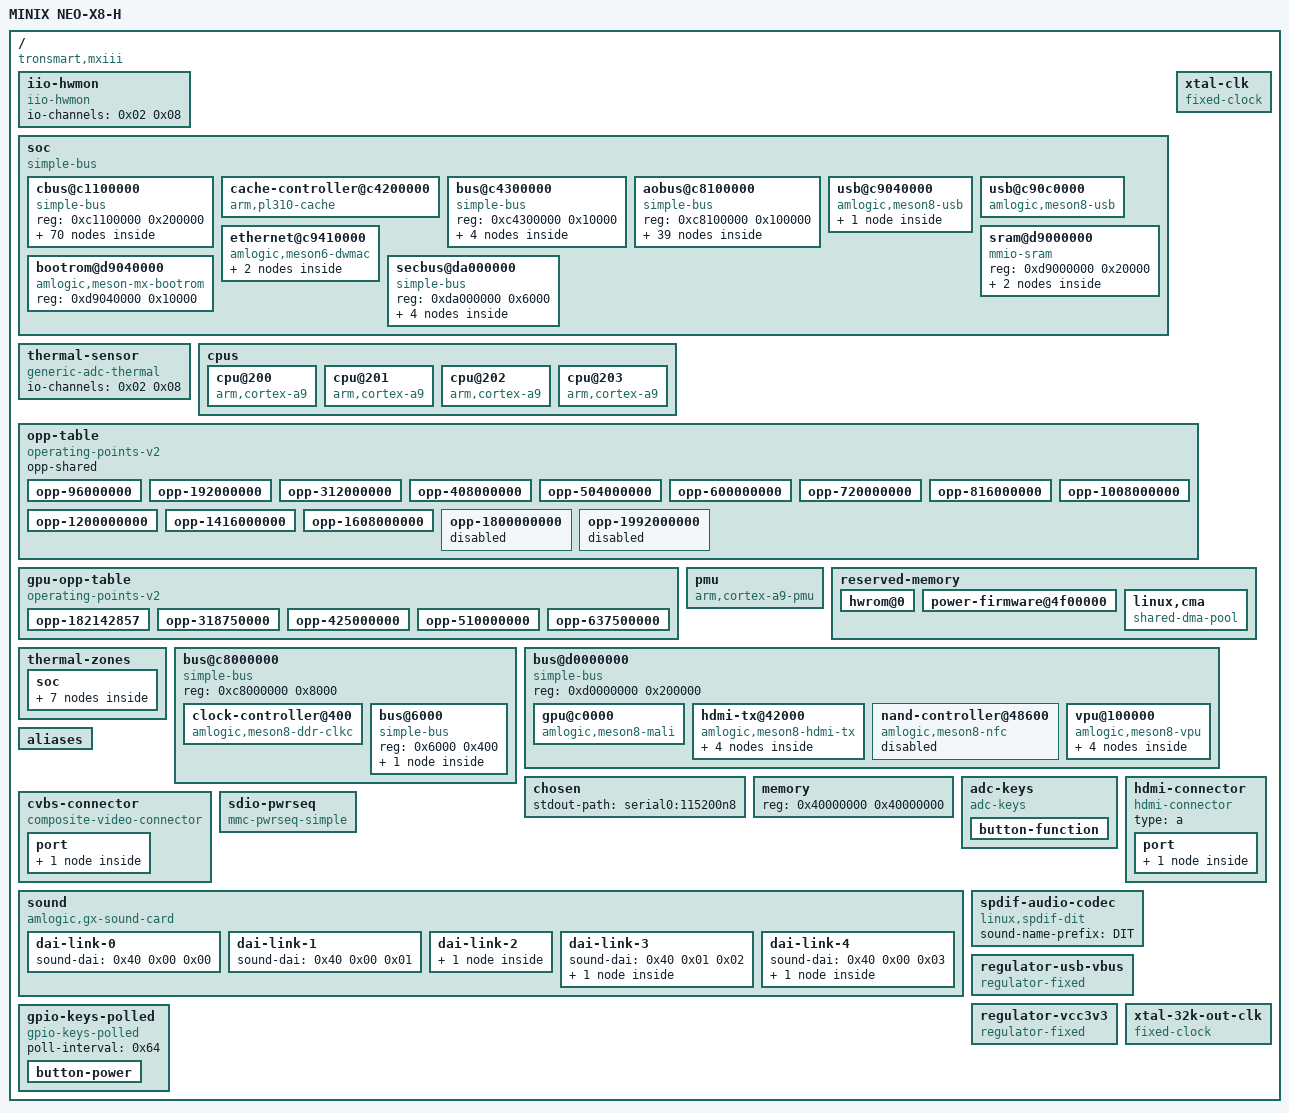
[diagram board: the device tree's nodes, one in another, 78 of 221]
/dts-v1/;

/ {
	#address-cells = <0x01>;
	#size-cells = <0x01>;
	interrupt-parent = <0x01>;
	model = "MINIX NEO-X8-H";
	compatible = "tronsmart,mxiii", "amlogic,meson8m2";

	iio-hwmon {
		compatible = "iio-hwmon";
		io-channels = <0x02 0x08>;
	};

	soc {
		compatible = "simple-bus";
		#address-cells = <0x01>;
		#size-cells = <0x01>;
		ranges;

		cbus@c1100000 {
			compatible = "simple-bus";
			reg = <0xc1100000 0x200000>;
			#address-cells = <0x01>;
			#size-cells = <0x01>;
			ranges = <0x00 0xc1100000 0x200000>;

			system-controller@4000 {
				compatible = "amlogic,meson-hhi-sysctrl", "simple-mfd", "syscon";
				reg = <0x4000 0x400>;
				#address-cells = <0x01>;
				#size-cells = <0x01>;
				ranges = <0x00 0x4000 0x400>;
				phandle = <0x0e>;

				video-dac@2f4 {
					compatible = "amlogic,meson8-cvbs-dac", "amlogic,meson-cvbs-dac";
					reg = <0x2f4 0x08>;
					#phy-cells = <0x00>;
					status = "okay";
					clocks = <0x03 0xab>;
					nvmem-cells = <0x04>;
					nvmem-cell-names = "cvbs_trimming";
					phandle = <0x38>;
				};

				clock-controller@0 {
					compatible = "amlogic,meson8-clkc";
					reg = <0x00 0x39c>;
					clocks = <0x05 0x06 0x01>;
					clock-names = "xtal", "ddr_pll";
					#clock-cells = <0x01>;
					#reset-cells = <0x01>;
					phandle = <0x03>;
				};

				power-controller@100 {
					compatible = "amlogic,meson8-pwrc";
					reg = <0x100 0x10>;
					#power-domain-cells = <0x01>;
					amlogic,ao-sysctrl = <0x07>;
					clocks = <0x03 0xbe>;
					clock-names = "vpu";
					assigned-clocks = <0x03 0xbe>;
					assigned-clock-rates = <0x15b68f12>;
					phandle = <0x21>;
				};

				hdmi-phy@3a0 {
					compatible = "amlogic,meson8-hdmi-tx-phy";
					clocks = <0x03 0x84>;
					reg = <0x3a0 0x0c>;
					#phy-cells = <0x00>;
					phandle = <0x32>;
				};
			};

			audio-controller@5400 {
				compatible = "amlogic,aiu-meson8", "amlogic,aiu";
				#sound-dai-cells = <0x02>;
				sound-name-prefix = "AIU";
				reg = <0x5400 0x2ac>;
				interrupts = <0x00 0x30 0x01 0x00 0x32 0x01>;
				interrupt-names = "i2s", "spdif";
				status = "okay";
				clocks = <0x03 0x26 0x03 0x28 0x03 0x50 0x03 0xd1 0x03 0x2c 0x03 0x27 0x03 0x51 0x03 0xd4 0x03 0xd5>;
				clock-names = "pclk", "i2s_pclk", "i2s_aoclk", "i2s_mclk", "i2s_mixer", "spdif_pclk", "spdif_aoclk", "spdif_mclk", "spdif_mclk_sel";
				resets = <0x08 0x06>;
				pinctrl-0 = <0x09 0x0a 0x0b 0x0c 0x0d>;
				pinctrl-names = "default";
				phandle = <0x40>;
			};

			assist@7c00 {
				compatible = "amlogic,meson-mx-assist", "syscon";
				reg = <0x7c00 0x200>;
			};

			rng@8100 {
				compatible = "amlogic,meson8-rng", "amlogic,meson-rng";
				reg = <0x8100 0x08>;
				clocks = <0x03 0x19>;
				clock-names = "core";
			};

			serial@84c0 {
				compatible = "amlogic,meson8-uart";
				reg = <0x84c0 0x18>;
				interrupts = <0x00 0x1a 0x01>;
				fifo-size = <0x80>;
				status = "disabled";
				clocks = <0x05 0x03 0x1a 0x03 0x0a>;
				clock-names = "xtal", "pclk", "baud";
			};

			serial@84dc {
				compatible = "amlogic,meson8-uart";
				reg = <0x84dc 0x18>;
				interrupts = <0x00 0x4b 0x01>;
				status = "disabled";
				clocks = <0x05 0x03 0x30 0x03 0x0a>;
				clock-names = "xtal", "pclk", "baud";
			};

			i2c@8500 {
				compatible = "amlogic,meson6-i2c";
				reg = <0x8500 0x20>;
				interrupts = <0x00 0x15 0x01>;
				#address-cells = <0x01>;
				#size-cells = <0x00>;
				status = "disabled";
				clocks = <0x03 0x0a>;
			};

			pwm@8550 {
				compatible = "amlogic,meson8-pwm", "amlogic,meson8b-pwm";
				reg = <0x8550 0x10>;
				#pwm-cells = <0x03>;
				status = "disabled";
			};

			pwm@8650 {
				compatible = "amlogic,meson8-pwm", "amlogic,meson8b-pwm";
				reg = <0x8650 0x10>;
				#pwm-cells = <0x03>;
				status = "disabled";
			};

			adc@8680 {
				compatible = "amlogic,meson8-saradc", "amlogic,meson-saradc";
				reg = <0x8680 0x34>;
				#io-channel-cells = <0x01>;
				interrupts = <0x00 0x49 0x01>;
				status = "okay";
				clocks = <0x05 0x03 0x17>;
				clock-names = "clkin", "core";
				amlogic,hhi-sysctrl = <0x0e>;
				nvmem-cells = <0x0f>;
				nvmem-cell-names = "temperature_calib";
				vref-supply = <0x10>;
				phandle = <0x02>;
			};

			serial@8700 {
				compatible = "amlogic,meson8-uart";
				reg = <0x8700 0x18>;
				interrupts = <0x00 0x5d 0x01>;
				status = "disabled";
				clocks = <0x05 0x03 0x44 0x03 0x0a>;
				clock-names = "xtal", "pclk", "baud";
			};

			i2c@87c0 {
				compatible = "amlogic,meson6-i2c";
				reg = <0x87c0 0x20>;
				interrupts = <0x00 0x80 0x01>;
				#address-cells = <0x01>;
				#size-cells = <0x00>;
				status = "disabled";
				clocks = <0x03 0x0a>;
			};

			phy@8800 {
				compatible = "amlogic,meson8-usb2-phy", "amlogic,meson-mx-usb2-phy";
				#phy-cells = <0x00>;
				reg = <0x8800 0x20>;
				gpio-controller;
				#gpio-cells = <0x02>;
				status = "okay";
				clocks = <0x03 0x37 0x03 0x32>;
				clock-names = "usb_general", "usb";
				resets = <0x08 0x22>;
				phandle = <0x1e>;
			};

			phy@8820 {
				compatible = "amlogic,meson8-usb2-phy", "amlogic,meson-mx-usb2-phy";
				#phy-cells = <0x00>;
				reg = <0x8820 0x20>;
				status = "okay";
				clocks = <0x03 0x37 0x03 0x33>;
				clock-names = "usb_general", "usb";
				resets = <0x08 0x22>;
				phandle = <0x20>;
			};

			mmc@8c20 {
				compatible = "amlogic,meson8-sdio", "amlogic,meson-mx-sdio";
				reg = <0x8c20 0x20>;
				interrupts = <0x00 0x1c 0x01>;
				#address-cells = <0x01>;
				#size-cells = <0x00>;
				status = "okay";
				clocks = <0x03 0x1e 0x03 0x0a>;
				clock-names = "core", "clkin";
				pinctrl-0 = <0x11>;
				pinctrl-names = "default";

				slot@0 {
					compatible = "mmc-slot";
					reg = <0x01>;
					bus-width = <0x04>;
					max-frequency = <0x2faf080>;
					no-mmc;
					no-sdio;
					cap-sd-highspeed;
					disable-wp;
					cd-gpios = <0x12 0x64 0x01>;
					vmmc-supply = <0x13>;
				};
			};

			spi@8c80 {
				compatible = "amlogic,meson6-spifc";
				reg = <0x8c80 0x80>;
				#address-cells = <0x01>;
				#size-cells = <0x00>;
				status = "disabled";
				clocks = <0x03 0x0a>;
			};

			/* SDHC: AP6330 (BCM4330) WiFi on the port-A / GPIOX pads */
			mmc@8e00 {
				compatible = "amlogic,meson8-sdhc", "amlogic,meson-mx-sdhc";
				reg = <0x8e00 0x42>;
				interrupts = <0x00 0x4e 0x01>;
				status = "okay";
				clocks = <0x05 0x03 0x07 0x03 0x06 0x03 0x08 0x03 0x1b>;
				clock-names = "clkin0", "clkin1", "clkin2", "clkin3", "pclk";
				pinctrl-0 = <0x51>;
				pinctrl-names = "default";
				#address-cells = <0x01>;
				#size-cells = <0x00>;
				bus-width = <0x04>;
				max-frequency = <0x17d7840>;
				disable-wp;
				non-removable;
				no-mmc;
				no-sd;
				cap-sd-highspeed;
				keep-power-in-suspend;
				mmc-pwrseq = <0x15>;
				vmmc-supply = <0x13>;
				vqmmc-supply = <0x13>;

				wifi@1 {
					compatible = "brcm,bcm4329-fmac";
					reg = <0x01>;
					/*
					 * Out-of-band host-wake on GPIOX_21 (from Android wifi/interrupt_pin),
					 * active-high level. REQUIRES the irq-meson-gpio IRQCHIP_SKIP_SET_WAKE
					 * kernel patch; without it brcmfmac enable_irq_wake() aborts with -6.
					 * interrupt-parent 0x24 = interrupt-controller@9880 (meson8-gpio-intc).
					 */
					interrupt-parent = <0x24>;
					interrupts = <0x15 0x04>;
					interrupt-names = "host-wake";
				};
			};

			interrupt-controller@9880 {
				compatible = "amlogic,meson8-gpio-intc", "amlogic,meson-gpio-intc";
				reg = <0x9880 0x10>;
				interrupt-controller;
				#interrupt-cells = <0x02>;
				amlogic,channel-interrupts = <0x40 0x41 0x42 0x43 0x44 0x45 0x46 0x47>;
				status = "okay";
				phandle = <0x24>;
			};

			watchdog@9900 {
				compatible = "amlogic,meson6-wdt";
				reg = <0x9900 0x08>;
				interrupts = <0x00 0x00 0x01>;
			};

			timer@9940 {
				compatible = "amlogic,meson6-timer";
				reg = <0x9940 0x18>;
				interrupts = <0x00 0x0a 0x01 0x00 0x0b 0x01 0x00 0x06 0x01 0x00 0x1d 0x01>;
				clocks = <0x05 0x03 0x0a>;
				clock-names = "xtal", "pclk";
			};

			reset-controller@4404 {
				compatible = "amlogic,meson8b-reset";
				reg = <0x4404 0x9c>;
				#reset-cells = <0x01>;
				phandle = <0x08>;
			};

			analog-top@81a8 {
				compatible = "amlogic,meson8-analog-top", "syscon";
				reg = <0x81a8 0x14>;
			};

			pwm@86c0 {
				compatible = "amlogic,meson8-pwm", "amlogic,meson8b-pwm";
				reg = <0x86c0 0x10>;
				#pwm-cells = <0x03>;
				status = "disabled";
			};

			clock-measure@8758 {
				compatible = "amlogic,meson8-clk-measure";
				reg = <0x8758 0x1c>;
			};

			pinctrl@9880 {
				compatible = "amlogic,meson8-cbus-pinctrl";
				reg = <0x9880 0x10>;
				#address-cells = <0x01>;
				#size-cells = <0x01>;
				ranges;
				phandle = <0x16>;

				banks@80b0 {
					reg = <0x80b0 0x28 0x80e8 0x18 0x8120 0x18 0x8030 0x30>;
					reg-names = "mux", "pull", "pull-enable", "gpio";
					gpio-controller;
					#gpio-cells = <0x02>;
					gpio-ranges = <0x16 0x00 0x00 0x78>;
					phandle = <0x12>;
				};

				hdmi-hpd {
					phandle = <0x33>;

					mux {
						groups = "hdmi_hpd";
						function = "hdmi";
						bias-disable;
					};
				};

				hdmi-i2c {
					phandle = <0x34>;

					mux {
						groups = "hdmi_sda", "hdmi_scl";
						function = "hdmi";
						bias-disable;
					};
				};

				pwm-c-dv9 {

					mux {
						groups = "pwm_c_dv9";
						function = "pwm_c";
					};
				};

				pwm-d {

					mux {
						groups = "pwm_d";
						function = "pwm_d";
					};
				};

				sd-a {

					mux {
						groups = "sd_d0_a", "sd_d1_a", "sd_d2_a", "sd_d3_a", "sd_clk_a", "sd_cmd_a";
						function = "sd_a";
						bias-disable;
					};
				};

				sd-b {
					phandle = <0x11>;

					mux {
						groups = "sd_d0_b", "sd_d1_b", "sd_d2_b", "sd_d3_b", "sd_clk_b", "sd_cmd_b";
						function = "sd_b";
						bias-disable;
					};
				};

				sd-c {

					mux {
						groups = "sd_d0_c", "sd_d1_c", "sd_d2_c", "sd_d3_c", "sd_clk_c", "sd_cmd_c";
						function = "sd_c";
						bias-disable;
					};
				};

				sdxc-a {
					phandle = <0x51>;

					mux {
						groups = "sdxc_d0_a", "sdxc_d13_a", "sdxc_clk_a", "sdxc_cmd_a";
						function = "sdxc_a";
						bias-pull-up;
					};
				};

				sdxc-b {
					phandle = <0x14>;

					mux {
						groups = "sdxc_d0_b", "sdxc_d13_b", "sdxc_clk_b", "sdxc_cmd_b";
						function = "sdxc_b";
						bias-pull-up;
					};
				};

				spdif-out {
					phandle = <0x0d>;

					mux {
						groups = "spdif_out";
						function = "spdif";
						bias-disable;
					};
				};

				nor {

					mux {
						groups = "nor_d", "nor_q", "nor_c", "nor_cs";
						function = "nor";
						bias-disable;
					};
				};

				ethernet {
					phandle = <0x22>;

					mux {
						groups = "eth_tx_clk_50m", "eth_tx_en", "eth_txd1", "eth_txd0", "eth_rx_clk_in", "eth_rx_dv", "eth_rxd1", "eth_rxd0", "eth_mdio", "eth_mdc";
						function = "ethernet";
						bias-disable;
					};
				};

				nand {

					mux {
						groups = "nand_io", "nand_ale", "nand_cle", "nand_wen_clk", "nand_ren_clk", "nand_dqs";
						function = "nand";
						bias-pull-down;
					};
				};

				nand-ce0 {

					mux {
						groups = "nand_io_ce0";
						function = "nand";
						bias-pull-up;
					};
				};

				nand-rb0 {

					mux {
						groups = "nand_io_rb0";
						function = "nand";
						bias-pull-up;
					};
				};

				pwm-e {

					mux {
						groups = "pwm_e";
						function = "pwm_e";
						bias-disable;
					};
				};

				uart-a1 {

					mux {
						groups = "uart_tx_a1", "uart_rx_a1";
						function = "uart_a";
						bias-disable;
					};
				};

				uart-a1-cts-rts {

					mux {
						groups = "uart_cts_a1", "uart_rts_a1";
						function = "uart_a";
						bias-disable;
					};
				};

				xtal-32k-out {
					phandle = <0x3d>;

					mux {
						groups = "xtal_32k_out";
						function = "xtal";
						bias-disable;
					};
				};
			};
		};

		cache-controller@c4200000 {
			compatible = "arm,pl310-cache";
			reg = <0xc4200000 0x1000>;
			cache-unified;
			cache-level = <0x02>;
			arm,data-latency = <0x03 0x03 0x03>;
			arm,tag-latency = <0x02 0x02 0x02>;
			arm,filter-ranges = <0x100000 0xc0000000>;
			prefetch-data = <0x01>;
			prefetch-instr = <0x01>;
			arm,prefetch-offset = <0x07>;
			arm,double-linefill = <0x01>;
			arm,prefetch-drop = <0x01>;
			arm,shared-override;
			phandle = <0x25>;
		};

		bus@c4300000 {
			compatible = "simple-bus";
			reg = <0xc4300000 0x10000>;
			#address-cells = <0x01>;
			#size-cells = <0x01>;
			ranges = <0x00 0xc4300000 0x10000>;

			interrupt-controller@1000 {
				compatible = "arm,cortex-a9-gic";
				reg = <0x1000 0x1000 0x100 0x100>;
				interrupt-controller;
				#interrupt-cells = <0x03>;
				phandle = <0x01>;
			};

			scu@0 {
				compatible = "arm,cortex-a9-scu";
				reg = <0x00 0x100>;
			};

			timer@200 {
				compatible = "arm,cortex-a9-global-timer";
				reg = <0x200 0x20>;
				interrupts = <0x01 0x0b 0xf01>;
				clocks = <0x03 0x7e>;
				status = "disabled";
			};

			timer@600 {
				compatible = "arm,cortex-a9-twd-timer";
				reg = <0x600 0x20>;
				interrupts = <0x01 0x0d 0xf01>;
				clocks = <0x03 0x7e>;
			};
		};

		aobus@c8100000 {
			compatible = "simple-bus";
			reg = <0xc8100000 0x100000>;
			#address-cells = <0x01>;
			#size-cells = <0x01>;
			ranges = <0x00 0xc8100000 0x100000>;

			remoteproc@1c {
				compatible = "amlogic,meson8-ao-arc", "amlogic,meson-mx-ao-arc";
				reg = <0x1c 0x08 0x38 0x08>;
				reg-names = "remap", "cpu";
				status = "disabled";
				amlogic,secbus2 = <0x17>;
				sram = <0x18>;
				resets = <0x08 0x4d>;
				clocks = <0x03 0x59>;
			};

			ir-receiver@480 {
				compatible = "amlogic,meson6-ir";
				reg = <0x480 0x20>;
				interrupts = <0x00 0x0f 0x01>;
				status = "okay";
				pinctrl-0 = <0x19>;
				pinctrl-names = "default";
			};

			serial@4c0 {
				compatible = "amlogic,meson8-uart", "amlogic,meson-ao-uart";
				reg = <0x4c0 0x18>;
				interrupts = <0x00 0x5a 0x01>;
				status = "okay";
				clocks = <0x05 0x03 0x0a 0x03 0x0a>;
				clock-names = "xtal", "pclk", "baud";
				pinctrl-0 = <0x1a>;
				pinctrl-names = "default";
			};

			i2c@500 {
				compatible = "amlogic,meson6-i2c";
				reg = <0x500 0x20>;
				interrupts = <0x00 0x5c 0x01>;
				#address-cells = <0x01>;
				#size-cells = <0x00>;
				status = "okay";
				clocks = <0x03 0x0a>;
				pinctrl-0 = <0x1b>;
				pinctrl-names = "default";

				pmic@32 {
					compatible = "ricoh,rn5t618";
					reg = <0x32>;
					system-power-controller;

					regulators {

						DCDC1 {
							regulator-name = "VCCK";
							regulator-min-microvolt = <0xc96a8>;
							regulator-max-microvolt = <0x118c30>;
							regulator-boot-on;
							regulator-always-on;
							phandle = <0x27>;
						};

						DCDC2 {
							regulator-name = "VDD_EE";
							regulator-min-microvolt = <0xe7ef0>;
							regulator-max-microvolt = <0x118c30>;
							regulator-boot-on;
							regulator-always-on;
							phandle = <0x31>;
						};

						DCDC3 {
							regulator-name = "VDD_DDR";
							regulator-min-microvolt = <0x16e360>;
							regulator-max-microvolt = <0x16e360>;
							regulator-boot-on;
							regulator-always-on;
						};

						LDO1 {
							regulator-name = "VDDIO_AO28";
							regulator-min-microvolt = <0x2c4020>;
							regulator-max-microvolt = <0x2c4020>;
							regulator-boot-on;
							regulator-always-on;
						};

						LDO2 {
							regulator-name = "VDDIO_AO18";
							regulator-min-microvolt = <0x1b7740>;
							regulator-max-microvolt = <0x1b7740>;
							regulator-boot-on;
							regulator-always-on;
							phandle = <0x10>;
						};

						LDO3 {
							regulator-name = "VCC1V8";
							regulator-min-microvolt = <0x1b7740>;
							regulator-max-microvolt = <0x1b7740>;
							regulator-boot-on;
							regulator-always-on;
						};

						LDO4 {
							regulator-name = "VCC2V8";
							regulator-min-microvolt = <0x2b7cd0>;
							regulator-max-microvolt = <0x2b7cd0>;
							regulator-boot-on;
							regulator-always-on;
						};

						LDO5 {
							regulator-name = "AVDD1V8";
							regulator-min-microvolt = <0x1b7740>;
							regulator-max-microvolt = <0x1b7740>;
							regulator-boot-on;
							regulator-always-on;
						};

						LDORTC1 {
							regulator-name = "VDD_LDO";
							regulator-min-microvolt = <0x2932e0>;
							regulator-max-microvolt = <0x2932e0>;
							regulator-boot-on;
							regulator-always-on;
						};

						LDORTC2 {
							regulator-name = "RTC_0V9";
							regulator-min-microvolt = <0xdbba0>;
							regulator-max-microvolt = <0xdbba0>;
							regulator-boot-on;
							regulator-always-on;
						};
					};
				};
			};

			rtc@740 {
				compatible = "amlogic,meson8-rtc";
				reg = <0x740 0x14>;
				interrupts = <0x00 0x48 0x01>;
				#address-cells = <0x01>;
				#size-cells = <0x01>;
				status = "disabled";
				resets = <0x08 0x8a>;
			};

			pmu@e0 {
				compatible = "amlogic,meson8-pmu", "syscon";
				reg = <0xe0 0x18>;
				phandle = <0x07>;
			};

			pinctrl@84 {
				compatible = "amlogic,meson8-aobus-pinctrl";
				reg = <0x84 0x0c>;
				#address-cells = <0x01>;
				#size-cells = <0x01>;
				ranges;
				phandle = <0x1c>;

				ao-bank@14 {
					reg = <0x14 0x04 0x2c 0x04 0x24 0x08>;
					reg-names = "mux", "pull", "gpio";
					gpio-controller;
					#gpio-cells = <0x02>;
					gpio-ranges = <0x1c 0x00 0x00 0x10>;
					phandle = <0x3e>;
				};

				hdmi-cec-ao {

					mux {
						groups = "hdmi_cec_ao";
						function = "hdmi_cec_ao";
						bias-pull-up;
					};
				};

				i2s-am-clk-out {
					phandle = <0x09>;

					mux {
						groups = "i2s_am_clk_out_ao";
						function = "i2s_ao";
						bias-disable;
					};
				};

				i2s-ao-clk-out {
					phandle = <0x0a>;

					mux {
						groups = "i2s_ao_clk_out_ao";
						function = "i2s_ao";
						bias-disable;
					};
				};

				i2s-lr-clk-out {
					phandle = <0x0b>;

					mux {
						groups = "i2s_lr_clk_out_ao";
						function = "i2s_ao";
						bias-disable;
					};
				};

				i2s-out-ch01 {
					phandle = <0x0c>;

					mux {
						groups = "i2s_out_ch01_ao";
						function = "i2s_ao";
						bias-disable;
					};
				};

				uart_ao_a {
					phandle = <0x1a>;

					mux {
						groups = "uart_tx_ao_a", "uart_rx_ao_a";
						function = "uart_ao";
						bias-disable;
					};
				};

				i2c_mst_ao {
					phandle = <0x1b>;

					mux {
						groups = "i2c_mst_sck_ao", "i2c_mst_sda_ao";
						function = "i2c_mst_ao";
						bias-disable;
					};
				};

				remote {
					phandle = <0x19>;

					mux {
						groups = "remote_input";
						function = "remote";
						bias-disable;
					};
				};

				pwm-f-ao {

					mux {
						groups = "pwm_f_ao";
						function = "pwm_f_ao";
						bias-disable;
					};
				};
			};

			cec@100 {
				compatible = "amlogic,meson-gx-ao-cec";
				reg = <0x100 0x14>;
				interrupts = <0x00 0x97 0x01>;
				hdmi-phandle = <0x1d>;
				status = "disabled";
			};
		};

		usb@c9040000 {
			compatible = "amlogic,meson8-usb", "snps,dwc2";
			#address-cells = <0x01>;
			#size-cells = <0x00>;
			reg = <0xc9040000 0x40000>;
			interrupts = <0x00 0x1e 0x04>;
			phys = <0x1e>;
			phy-names = "usb2-phy";
			g-rx-fifo-size = <0x200>;
			g-np-tx-fifo-size = <0x1f4>;
			g-tx-fifo-size = <0x100 0xc0 0x80 0x80 0x80>;
			dr_mode = "otg";
			status = "okay";
			clocks = <0x03 0x41>;
			clock-names = "otg";
			usb-role-switch;

			connector {
				compatible = "gpio-usb-b-connector", "usb-b-connector";
				type = "micro";
				id-gpios = <0x1e 0x00 0x00>;
				vbus-supply = <0x1f>;
			};
		};

		usb@c90c0000 {
			compatible = "amlogic,meson8-usb", "snps,dwc2";
			#address-cells = <0x01>;
			#size-cells = <0x00>;
			reg = <0xc90c0000 0x40000>;
			interrupts = <0x00 0x1f 0x04>;
			phys = <0x20>;
			phy-names = "usb2-phy";
			dr_mode = "host";
			status = "okay";
			clocks = <0x03 0x40>;
			clock-names = "otg";
		};

		ethernet@c9410000 {
			compatible = "amlogic,meson6-dwmac", "snps,dwmac";
			reg = <0xc9410000 0x10000 0xc1108108 0x04>;
			interrupts = <0x00 0x08 0x04>;
			interrupt-names = "macirq";
			status = "okay";
			clocks = <0x03 0x24 0x03 0xdd>;
			clock-names = "stmmaceth", "ethernet";
			power-domains = <0x21 0x01>;
			pinctrl-0 = <0x22>;
			pinctrl-names = "default";
			phy-handle = <0x23>;
			phy-mode = "rmii";

			mdio {
				compatible = "snps,dwmac-mdio";
				#address-cells = <0x01>;
				#size-cells = <0x00>;

				ethernet-phy@0 {
					reg = <0x00>;
					icplus,select-interrupt;
					interrupt-parent = <0x24>;
					reset-assert-us = <0x2710>;
					reset-deassert-us = <0x2710>;
					reset-gpios = <0x12 0x5d 0x01>;
					phandle = <0x23>;
				};
			};
		};

		sram@d9000000 {
			compatible = "mmio-sram";
			reg = <0xd9000000 0x20000>;
			#address-cells = <0x01>;
			#size-cells = <0x01>;
			ranges = <0x00 0xd9000000 0x20000>;

			ao-arc-sram@0 {
				compatible = "amlogic,meson8-ao-arc-sram";
				reg = <0x00 0x8000>;
				pool;
				phandle = <0x18>;
			};

			smp-sram@1ff80 {
				compatible = "amlogic,meson8-smp-sram";
				reg = <0x1ff80 0x08>;
			};
		};

		bootrom@d9040000 {
			compatible = "amlogic,meson-mx-bootrom", "syscon";
			reg = <0xd9040000 0x10000>;
		};

		secbus@da000000 {
			compatible = "simple-bus";
			reg = <0xda000000 0x6000>;
			#address-cells = <0x01>;
			#size-cells = <0x01>;
			ranges = <0x00 0xda000000 0x6000>;

			nvmem@0 {
				compatible = "amlogic,meson8-efuse";
				reg = <0x00 0x2000>;
				#address-cells = <0x01>;
				#size-cells = <0x01>;
				clocks = <0x03 0x3a>;
				clock-names = "core";

				calib@1f4 {
					reg = <0x1f4 0x04>;
					phandle = <0x0f>;
				};

				calib@1f8 {
					reg = <0x1f8 0x02>;
					phandle = <0x04>;
				};
			};

			system-controller@4000 {
				compatible = "amlogic,meson8-secbus2", "syscon";
				reg = <0x4000 0x2000>;
				phandle = <0x17>;
			};
		};
	};

	thermal-sensor {
		compatible = "generic-adc-thermal";
		#thermal-sensor-cells = <0x00>;
		io-channels = <0x02 0x08>;
		io-channel-names = "sensor-channel";
		phandle = <0x2c>;
	};

	xtal-clk {
		compatible = "fixed-clock";
		clock-frequency = <0x16e3600>;
		clock-output-names = "xtal";
		#clock-cells = <0x00>;
		phandle = <0x05>;
	};

	cpus {
		#address-cells = <0x01>;
		#size-cells = <0x00>;

		cpu@200 {
			device_type = "cpu";
			compatible = "arm,cortex-a9";
			next-level-cache = <0x25>;
			reg = <0x200>;
			enable-method = "amlogic,meson8-smp";
			resets = <0x03 0x03>;
			operating-points-v2 = <0x26>;
			clocks = <0x03 0x0c>;
			#cooling-cells = <0x02>;
			cpu-supply = <0x27>;
			phandle = <0x28>;
		};

		cpu@201 {
			device_type = "cpu";
			compatible = "arm,cortex-a9";
			next-level-cache = <0x25>;
			reg = <0x201>;
			enable-method = "amlogic,meson8-smp";
			resets = <0x03 0x04>;
			operating-points-v2 = <0x26>;
			clocks = <0x03 0x0c>;
			#cooling-cells = <0x02>;
			phandle = <0x29>;
		};

		cpu@202 {
			device_type = "cpu";
			compatible = "arm,cortex-a9";
			next-level-cache = <0x25>;
			reg = <0x202>;
			enable-method = "amlogic,meson8-smp";
			resets = <0x03 0x05>;
			operating-points-v2 = <0x26>;
			clocks = <0x03 0x0c>;
			#cooling-cells = <0x02>;
			phandle = <0x2a>;
		};

		cpu@203 {
			device_type = "cpu";
			compatible = "arm,cortex-a9";
			next-level-cache = <0x25>;
			reg = <0x203>;
			enable-method = "amlogic,meson8-smp";
			resets = <0x03 0x06>;
			operating-points-v2 = <0x26>;
			clocks = <0x03 0x0c>;
			#cooling-cells = <0x02>;
			phandle = <0x2b>;
		};
	};

	opp-table {
		compatible = "operating-points-v2";
		opp-shared;
		phandle = <0x26>;

		opp-96000000 {
			opp-hz = <0x00 0x5b8d800>;
			opp-microvolt = <0xc96a8>;
		};

		opp-192000000 {
			opp-hz = <0x00 0xb71b000>;
			opp-microvolt = <0xc96a8>;
		};

		opp-312000000 {
			opp-hz = <0x00 0x1298be00>;
			opp-microvolt = <0xc96a8>;
		};

		opp-408000000 {
			opp-hz = <0x00 0x18519600>;
			opp-microvolt = <0xc96a8>;
		};

		opp-504000000 {
			opp-hz = <0x00 0x1e0a6e00>;
			opp-microvolt = <0xc96a8>;
		};

		opp-600000000 {
			opp-hz = <0x00 0x23c34600>;
			opp-microvolt = <0xcf850>;
		};

		opp-720000000 {
			opp-hz = <0x00 0x2aea5400>;
			opp-microvolt = <0xcf850>;
		};

		opp-816000000 {
			opp-hz = <0x00 0x30a32c00>;
			opp-microvolt = <0xd59f8>;
		};

		opp-1008000000 {
			opp-hz = <0x00 0x3c14dc00>;
			opp-microvolt = <0xe1d48>;
		};

		opp-1200000000 {
			opp-hz = <0x00 0x47868c00>;
			opp-microvolt = <0xee098>;
		};

		opp-1416000000 {
			opp-hz = <0x00 0x54667200>;
			opp-microvolt = <0xfa3e8>;
		};

		opp-1608000000 {
			opp-hz = <0x00 0x5fd82200>;
			opp-microvolt = <0x10c8e0>;
		};

		opp-1800000000 {
			status = "disabled";
			opp-hz = <0x00 0x6b49d200>;
			opp-microvolt = <0x112a88>;
		};

		opp-1992000000 {
			status = "disabled";
			opp-hz = <0x00 0x76bb8200>;
			opp-microvolt = <0x118c30>;
		};
	};

	gpu-opp-table {
		compatible = "operating-points-v2";
		phandle = <0x30>;

		opp-182142857 {
			opp-hz = <0x00 0xadb4789>;
			opp-microvolt = <0x118c30>;
		};

		opp-318750000 {
			opp-hz = <0x00 0x12ffbd30>;
			opp-microvolt = <0x118c30>;
		};

		opp-425000000 {
			opp-hz = <0x00 0x1954fc40>;
			opp-microvolt = <0x118c30>;
		};

		opp-510000000 {
			opp-hz = <0x00 0x1e65fb80>;
			opp-microvolt = <0x118c30>;
		};

		opp-637500000 {
			opp-hz = <0x00 0x25ff7a60>;
			opp-microvolt = <0x118c30>;
			turbo-mode;
		};
	};

	pmu {
		compatible = "arm,cortex-a9-pmu";
		interrupts = <0x00 0x89 0x04 0x00 0x8a 0x04 0x00 0x99 0x04 0x00 0x9a 0x04>;
		interrupt-affinity = <0x28 0x29 0x2a 0x2b>;
	};

	reserved-memory {
		#address-cells = <0x01>;
		#size-cells = <0x01>;
		ranges;

		hwrom@0 {
			reg = <0x00 0x200000>;
			no-map;
		};

		power-firmware@4f00000 {
			reg = <0x4f00000 0x100000>;
			no-map;
		};

		linux,cma {
			compatible = "shared-dma-pool";
			reusable;
			size = <0x10000000>;
			alignment = <0x400000>;
			linux,cma-default;
		};
	};

	thermal-zones {

		soc {
			polling-delay-passive = <0xfa>;
			polling-delay = <0x3e8>;
			thermal-sensors = <0x2c>;

			cooling-maps {

				map0 {
					trip = <0x2d>;
					cooling-device = <0x28 0xffffffff 0xffffffff 0x29 0xffffffff 0xffffffff 0x2a 0xffffffff 0xffffffff 0x2b 0xffffffff 0xffffffff 0x2e 0xffffffff 0xffffffff>;
				};

				map1 {
					trip = <0x2f>;
					cooling-device = <0x28 0xffffffff 0xffffffff 0x29 0xffffffff 0xffffffff 0x2a 0xffffffff 0xffffffff 0x2b 0xffffffff 0xffffffff 0x2e 0xffffffff 0xffffffff>;
				};
			};

			trips {

				soc-passive {
					temperature = <0x13880>;
					hysteresis = <0x7d0>;
					type = "passive";
					phandle = <0x2d>;
				};

				soc-hot {
					temperature = <0x15f90>;
					hysteresis = <0x7d0>;
					type = "hot";
					phandle = <0x2f>;
				};

				soc-critical {
					temperature = <0x1adb0>;
					hysteresis = <0x7d0>;
					type = "critical";
				};
			};
		};
	};

	bus@c8000000 {
		compatible = "simple-bus";
		reg = <0xc8000000 0x8000>;
		#address-cells = <0x01>;
		#size-cells = <0x01>;
		ranges = <0x00 0xc8000000 0x8000>;

		clock-controller@400 {
			compatible = "amlogic,meson8-ddr-clkc";
			reg = <0x400 0x20>;
			clocks = <0x05>;
			clock-names = "xtal";
			#clock-cells = <0x01>;
			phandle = <0x06>;
		};

		bus@6000 {
			compatible = "simple-bus";
			reg = <0x6000 0x400>;
			#address-cells = <0x01>;
			#size-cells = <0x01>;
			ranges = <0x00 0x6000 0x400>;

			video-lut@20 {
				compatible = "amlogic,meson8-canvas", "amlogic,canvas";
				reg = <0x20 0x14>;
				phandle = <0x37>;
			};
		};
	};

	bus@d0000000 {
		compatible = "simple-bus";
		reg = <0xd0000000 0x200000>;
		#address-cells = <0x01>;
		#size-cells = <0x01>;
		ranges = <0x00 0xd0000000 0x200000>;

		gpu@c0000 {
			compatible = "amlogic,meson8-mali", "arm,mali-450";
			reg = <0xc0000 0x40000>;
			interrupts = <0x00 0xa0 0x04 0x00 0xa1 0x04 0x00 0xa2 0x04 0x00 0xa3 0x04 0x00 0xa4 0x04 0x00 0xa5 0x04 0x00 0xa6 0x04 0x00 0xa7 0x04 0x00 0xa8 0x04 0x00 0xa9 0x04 0x00 0xac 0x04 0x00 0xad 0x04 0x00 0xae 0x04 0x00 0xaf 0x04 0x00 0xb0 0x04 0x00 0xb1 0x04>;
			interrupt-names = "gp", "gpmmu", "pp", "pmu", "pp0", "ppmmu0", "pp1", "ppmmu1", "pp2", "ppmmu2", "pp4", "ppmmu4", "pp5", "ppmmu5", "pp6", "ppmmu6";
			resets = <0x08 0x4e>;
			clocks = <0x03 0x0a 0x03 0x0b>;
			clock-names = "bus", "core";
			assigned-clocks = <0x03 0x0b>;
			assigned-clock-rates = <0x12ffbd30>;
			operating-points-v2 = <0x30>;
			#cooling-cells = <0x02>;
			mali-supply = <0x31>;
			phandle = <0x2e>;
		};

		hdmi-tx@42000 {
			compatible = "amlogic,meson8-hdmi-tx";
			reg = <0x42000 0x0c>;
			interrupts = <0x00 0x39 0x01>;
			phys = <0x32>;
			phy-names = "hdmi";
			clocks = <0x03 0x3f 0x03 0xae>;
			clock-names = "pclk", "sys";
			#address-cells = <0x01>;
			#size-cells = <0x00>;
			#sound-dai-cells = <0x01>;
			sound-name-prefix = "HDMITX";
			status = "okay";
			pinctrl-0 = <0x33 0x34>;
			pinctrl-names = "default";
			phandle = <0x1d>;

			port@0 {
				reg = <0x00>;

				endpoint {
					remote-endpoint = <0x35>;
					phandle = <0x3a>;
				};
			};

			port@1 {
				reg = <0x01>;

				endpoint {
					remote-endpoint = <0x36>;
					phandle = <0x3c>;
				};
			};
		};

		nand-controller@48600 {
			compatible = "amlogic,meson8-nfc";
			reg = <0x48600 0x24>;
			interrupts = <0x00 0x22 0x01>;
			#address-cells = <0x01>;
			#size-cells = <0x00>;
			clocks = <0x03 0x35 0x03 0x70>;
			clock-names = "core", "nand";
			status = "disabled";
		};

		vpu@100000 {
			compatible = "amlogic,meson8-vpu";
			reg = <0x100000 0x10000>;
			reg-names = "vpu";
			interrupts = <0x00 0x03 0x01>;
			amlogic,canvas = <0x37>;
			assigned-clocks = <0x03 0x8a 0x03 0x95>;
			assigned-clock-parents = <0x03 0x89 0x03 0x89>;
			clocks = <0x03 0x46 0x03 0x3e 0x03 0x4d 0x03 0x84 0x03 0xa7 0x03 0xa3 0x03 0xa5 0x03 0xa1 0x03 0xa9 0x03 0xab>;
			clock-names = "vpu_intr", "hdmi_intr_sync", "venci_int", "tmds", "hdmi_tx_pixel", "cts_encp", "cts_enci", "cts_enct", "cts_encl", "cts_vdac0";
			resets = <0x03 0x0f 0x03 0x0e 0x03 0x0d 0x03 0x0c>;
			reset-names = "vid_pll_pre", "vid_pll_post", "vid_pll_soft_pre", "vid_pll_soft_post";
			phys = <0x38>;
			phy-names = "cvbs-dac";
			power-domains = <0x21 0x00>;
			#address-cells = <0x01>;
			#size-cells = <0x00>;

			port@0 {
				reg = <0x00>;

				endpoint {
					remote-endpoint = <0x39>;
					phandle = <0x3b>;
				};
			};

			port@1 {
				reg = <0x01>;

				endpoint {
					remote-endpoint = <0x3a>;
					phandle = <0x35>;
				};
			};
		};
	};

	aliases {
		ethernet0 = "/soc/ethernet@c9410000";
		i2c0 = "/soc/aobus@c8100000/i2c@500";
		serial0 = "/soc/aobus@c8100000/serial@4c0";
	};

	chosen {
		stdout-path = "serial0:115200n8";
	};

	memory {
		reg = <0x40000000 0x40000000>;
		device_type = "memory";
	};

	adc-keys {
		compatible = "adc-keys";
		io-channels = <0x02 0x00>;
		io-channel-names = "buttons";
		keyup-threshold-microvolt = <0x1a17b0>;

		button-function {
			label = "Function";
			linux,code = <0x1d0>;
			press-threshold-microvolt = <0x2710>;
		};
	};

	cvbs-connector {
		compatible = "composite-video-connector";

		port {

			endpoint {
				remote-endpoint = <0x3b>;
				phandle = <0x39>;
			};
		};
	};

	hdmi-connector {
		compatible = "hdmi-connector";
		type = "a";

		port {

			endpoint {
				remote-endpoint = <0x3c>;
				phandle = <0x36>;
			};
		};
	};

	sdio-pwrseq {
		compatible = "mmc-pwrseq-simple";
		pinctrl-0 = <0x3d>;
		pinctrl-names = "default";
		reset-gpios = <0x12 0x0b 0x01 0x3e 0x06 0x01>;
		clocks = <0x3f>;
		clock-names = "ext_clock";
		phandle = <0x15>;
	};

	sound {
		compatible = "amlogic,gx-sound-card";
		model = "TRONSMART-MXIII";
		assigned-clocks = <0x03 0x5d 0x03 0x5e>;
		assigned-clock-rates = <0x10266000 0x11940000>;

		dai-link-0 {
			sound-dai = <0x40 0x00 0x00>;
		};

		dai-link-1 {
			sound-dai = <0x40 0x00 0x01>;
		};

		dai-link-2 {
			sound-dai = <0x40 0x00 0x02>;
			dai-format = "i2s";
			mclk-fs = <0x100>;

			codec-0 {
				sound-dai = <0x40 0x01 0x00>;
			};
		};

		dai-link-3 {
			sound-dai = <0x40 0x01 0x02>;

			codec-0 {
				sound-dai = <0x1d 0x00>;
			};
		};

		dai-link-4 {
			sound-dai = <0x40 0x00 0x03>;

			codec-0 {
				sound-dai = <0x41>;
			};
		};
	};

	spdif-audio-codec {
		compatible = "linux,spdif-dit";
		#sound-dai-cells = <0x00>;
		sound-name-prefix = "DIT";
		phandle = <0x41>;
	};

	regulator-usb-vbus {
		compatible = "regulator-fixed";
		regulator-name = "USB_VBUS";
		regulator-min-microvolt = <0x4c4b40>;
		regulator-max-microvolt = <0x4c4b40>;
		gpio = <0x12 0x50 0x00>;
		enable-active-high;
		phandle = <0x1f>;
	};

	regulator-vcc3v3 {
		compatible = "regulator-fixed";
		regulator-name = "VCC3V3";
		regulator-min-microvolt = <0x325aa0>;
		regulator-max-microvolt = <0x325aa0>;
		phandle = <0x13>;
	};

	xtal-32k-out-clk {
		compatible = "fixed-clock";
		#clock-cells = <0x00>;
		clock-frequency = <0x8000>;
		clock-output-names = "xtal_32k_out";
		phandle = <0x3f>;
	};

	gpio-keys-polled {
		compatible = "gpio-keys-polled";
		poll-interval = <0x64>;

		button-power {
			label = "power";
			linux,code = <0x74>;
			gpios = <0x3e 0x03 0x01>;
		};
	};
};
